# ATtiny102 device description
Architecture: AVR8L; Family: tinyAVR
Registers are 8-bit, access not given, no defined reset value unless marked. A register's access mark holds for its fields unless they carry their own. Offsets are from the block's base; [hi:lo] are bit positions; {n}, {i} and the like mark numbered series.

## AC — Analog Comparator
Instances: AC 0x00
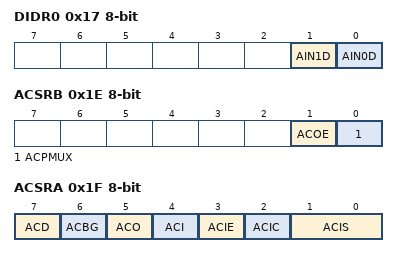
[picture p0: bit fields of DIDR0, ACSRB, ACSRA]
0x17 DIDR0
  [1] AIN1D — AIN1 Digital Input Disable
  [0] AIN0D — AIN0 Digital Input Disable
0x1E ACSRB — Analog Comparator Control And Status Register B
  [1] ACOE — Analog Comparator Output Enable
  [0] ACPMUX — Analog Comparator positive input selection bit
0x1F ACSRA — Analog Comparator Control And Status Register A
  [7] ACD — Analog Comparator Disable
  [6] ACBG — Analog Comparator Bandgap enable
  [5] ACO — Analog Compare Output
  [4] ACI — Analog Comparator Interrupt Flag
  [3] ACIE — Analog Comparator Interrupt Enable
  [2] ACIC — Analog Comparator Input Capture Enable
  [1:0] ACIS — Analog Comparator Interrupt Mode Select bits
    0=Interrupt on Toggle; 2=Interrupt on Falling Edge; 3=Interrupt on Rising Edge

## CPU — CPU Registers
Instances: CPU 0x00
Parameters: CORE_VERSION=AVR8L_0
0x32 NVMCSR — Non-Volatile Memory Control and Status Register
  [7] NVMBSY — Non-Volatile Memory Busy
0x33 NVMCMD bits used 5:0 — Non-Volatile Memory Command
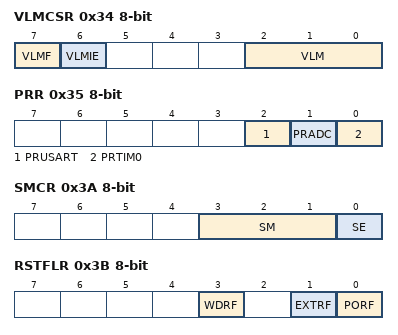
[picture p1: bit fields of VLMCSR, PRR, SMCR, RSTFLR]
0x34 VLMCSR — Vcc Level Monitoring Control and Status Register
  [7] VLMF — VLM Flag
  [6] VLMIE — VLM Interrupt Enable
  [2:0] VLM — Trigger Level of Voltage Level Monitor bits
0x35 PRR — Power Reduction Register
  [2] PRUSART — Power Reduction USART
  [1] PRADC — Power Reduction ADC
  [0] PRTIM0 — Power Reduction Timer/Counter0
0x36 CLKPSR — Clock Prescale Register
  [3:0] CLKPS — Clock Prescaler Select Bits
    0=1; 1=2; 2=4; 3=8; 4=16; 5=32; 6=64; 7=128; 8=256
0x37 CLKMSR — Clock Main Settings Register
  [1:0] CLKMS — Clock Main Select Bits
0x39 OSCCAL — Oscillator Calibration Value
0x3A SMCR — Sleep Mode Control Register
  [3:1] SM — Sleep Mode Select Bits
    0=IDLE; 1=ADC (ADC Noise Reduction); 2=PDOWN (Power Down); 4=STDBY (Standby)
  [0] SE — Sleep Enable
0x3B RSTFLR — Reset Flag Register
  [3] WDRF — Watchdog Reset Flag
  [1] EXTRF — External Reset Flag
  [0] PORF — Power-on Reset Flag
0x3C CCP — Configuration Change Protection
  [7:0] CCP rw — CCP signature
    231=SPM (SPM Instruction Protection); 216=IOREG (IO Register Protection)
0x3D SP 16-bit — Stack Pointer
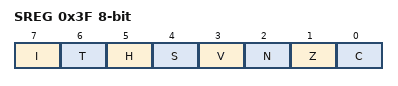
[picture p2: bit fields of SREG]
0x3F SREG — Status Register
  [7] I — Global Interrupt Enable
  [6] T — Bit Copy Storage
  [5] H — Half Carry Flag
  [4] S — Sign Bit
  [3] V — Two's Complement Overflow Flag
  [2] N — Negative Flag
  [1] Z — Zero Flag
  [0] C — Carry Flag

## PORTB — I/O Port
Instances: PORTB 0x00
0x04 PINB bits used 3:0 — Input Pins, Port B
0x05 DDRB bits used 3:0 — Data Direction Register, Port B
0x06 PORTB bits used 3:0 — Port B Data register
0x07 PUEB bits used 3:0 — Pull-up Enable Control Register for PORTB
0x16 PORTCR — Port Control Register
  [1] BBMB — Break-Before-Make Mode Enable for PORTB

## PORTA — I/O Port
Instances: PORTA 0x00
0x00 PINA — Input Pins, Port A
0x01 DDRA — Data Direction Register, Port A
0x02 PORTA — Port A Data register
0x03 PUEA — Pull-up Enable Control Register for PORTA
0x16 PORTCR — Port Control Register
  [0] BBMA — Break-Before-Make Mode Enable for PORTA

## EXINT — External Interrupts
Instances: EXINT 0x00
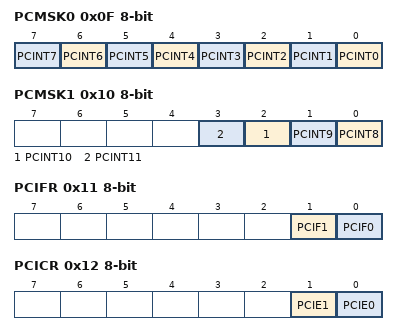
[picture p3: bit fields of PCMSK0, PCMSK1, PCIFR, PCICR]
0x0F PCMSK0 — Pin Change Mask Register 0
  [n] PCINT{n} (n=0..7) — Pin Change Enable Mask 0 Bit {n}
0x10 PCMSK1 — Pin Change Mask Register 1
  [n-8] PCINT{n} (n=8..11) — Pin Change Enable Mask 1 Bit {n-8}
0x11 PCIFR — Pin Change Interrupt Flag Register
  [1] PCIF1 — Pin Change Interrupt Flag 1
  [0] PCIF0 — Pin Change Interrupt Flag 0
0x12 PCICR — Pin Change Interrupt Control Register
  [1] PCIE1 — Pin Change Interrupt Enable 1
  [0] PCIE0 — Pin Change Interrupt Enable 0
0x13 EIMSK — External Interrupt Mask register
  [0] INT0 — External Interrupt Request 0 Enable
0x14 EIFR — External Interrupt Flag register
  [0] INTF0 — External Interrupt Flag 0
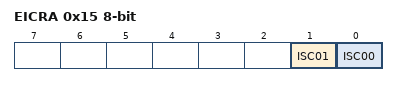
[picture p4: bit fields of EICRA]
0x15 EICRA — External Interrupt Control Register A
  [1] ISC01 — Interrupt Sense Control 0 Bit 1
  [0] ISC00 — Interrupt Sense Control 0 Bit 0

## TC0 (TC16 module) — Timer/Counter, 16-bit
Instances: TC0 0x00
0x22 ICR0 16-bit — Input Capture Register Bytes
0x24 OCR0B 16-bit — Timer/Counter0 Output Compare Register B
0x26 OCR0A 16-bit — Timer/Counter 0 Output Compare Register A
0x28 TCNT0 16-bit — Timer/Counter0
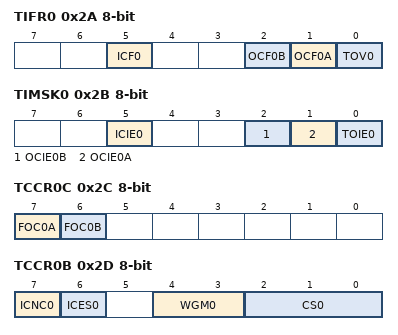
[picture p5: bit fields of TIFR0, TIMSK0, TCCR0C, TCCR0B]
0x2A TIFR0 — Overflow Interrupt Enable
  [5] ICF0 — Input Capture Flag
  [2] OCF0B — Timer Output Compare Flag 0B
  [1] OCF0A — Timer Output Compare Flag 0A
  [0] TOV0 — Timer Overflow Flag
0x2B TIMSK0 — Timer Interrupt Mask Register 0
  [5] ICIE0 — Input Capture Interrupt Enable
  [2] OCIE0B — Output Compare B Match Interrupt Enable
  [1] OCIE0A — Output Compare A Match Interrupt Enable
  [0] TOIE0 — Overflow Interrupt Enable
0x2C TCCR0C — Timer/Counter 0 Control Register C
  [7] FOC0A — Force Output Compare for Channel A
  [6] FOC0B — Force Output Compare for Channel B
0x2D TCCR0B — Timer/Counter 0 Control Register B
  [7] ICNC0 — Input Capture Noise Canceler
  [6] ICES0 — Input Capture Edge Select
  [4:3] WGM0 (bit 2 of the value upward) — Waveform Generation Mode
  [2:0] CS0 — Clock Select
    0=No Clock Source (Stopped); 1=Running, No Prescaling; 2=Running, CLK/8; 3=Running, CLK/64; 4=Running, CLK/256; 5=Running, CLK/1024; 6=Running, ExtClk Tx Falling Edge; 7=Running, ExtClk Tx Rising Edge
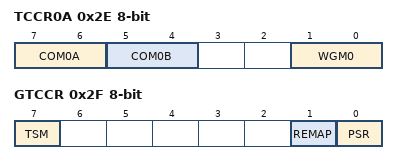
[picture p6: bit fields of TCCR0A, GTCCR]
0x2E TCCR0A — Timer/Counter 0 Control Register A
  [7:6] COM0A — Compare Output Mode for Channel A bits
  [5:4] COM0B — Compare Output Mode for Channel B bits
  [1:0] WGM0 — Waveform Generation Mode
0x2F GTCCR — General Timer/Counter Control Register
  [7] TSM — Timer Synchronization Mode
  [1] REMAP — Remap Bit for 14 pin part only
  [0] PSR — Prescaler Reset

## USART
Instances: USART 0
0x08 UDR — USART I/O Data Register
0x09 UBRR 16-bit bits used 11:0 — USART Baud Rate Register Bytes
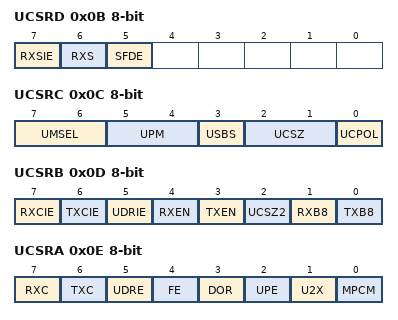
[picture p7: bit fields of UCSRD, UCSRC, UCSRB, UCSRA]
0x0B UCSRD — USART Control and Status Register D
  [7] RXSIE — USART RX Start Interrupt Enable
  [6] RXS — USART RX Start Flag
  [5] SFDE — Start frame detection enable
0x0C UCSRC — USART Control and Status Register C
  [7:6] UMSEL — USART Mode Select
    0=Asynchronous Operation; 1=Synchronous Operation
  [5:4] UPM — Parity Mode Bits
    0=Disabled; 2=Enabled, Even Parity; 3=Enabled, Odd Parity
  [3] USBS — Stop Bit Select
    0=1-bit; 1=2-bit
  [2:1] UCSZ — Character Size
  [0] UCPOL — Clock Polarity
0x0D UCSRB — USART Control and Status Register B
  [7] RXCIE — RX Complete Interrupt Enable
  [6] TXCIE — TX Complete Interrupt Enable
  [5] UDRIE — USART Data register Empty Interrupt Enable
  [4] RXEN — Receiver Enable
  [3] TXEN — Transmitter Enable
  [2] UCSZ2 — Character Size
  [1] RXB8 — Receive Data Bit 8
  [0] TXB8 — Transmit Data Bit 8
0x0E UCSRA — USART Control and Status Register A
  [7] RXC — USART Receive Complete
  [6] TXC — USART Transmitt Complete
  [5] UDRE — USART Data Register Empty
  [4] FE — Framing Error
  [3] DOR — Data overRun
  [2] UPE — Parity Error
  [1] U2X — Double the USART transmission speed
  [0] MPCM — Multi-processor Communication Mode

## WDT — Watchdog Timer
Instances: WDT 0x00
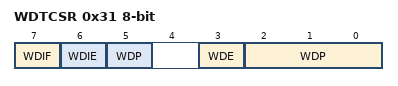
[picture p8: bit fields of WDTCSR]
0x31 WDTCSR — Watchdog Timer Control and Status Register
  [7] WDIF — Watchdog Timer Interrupt Flag
  [6] WDIE — Watchdog Timer Interrupt Enable
  [3] WDE — Watch Dog Enable
  [5,2:0] WDP — Watchdog Timer Prescaler Bits
    0=Oscillator Cycles 2K; 1=Oscillator Cycles 4K; 2=Oscillator Cycles 8K; 3=Oscillator Cycles 16K; 4=Oscillator Cycles 32K; 5=Oscillator Cycles 64K; 6=Oscillator Cycles 128K; 7=Oscillator Cycles 256K; 8=Oscillator Cycles 512K; 9=Oscillator Cycles 1024K
